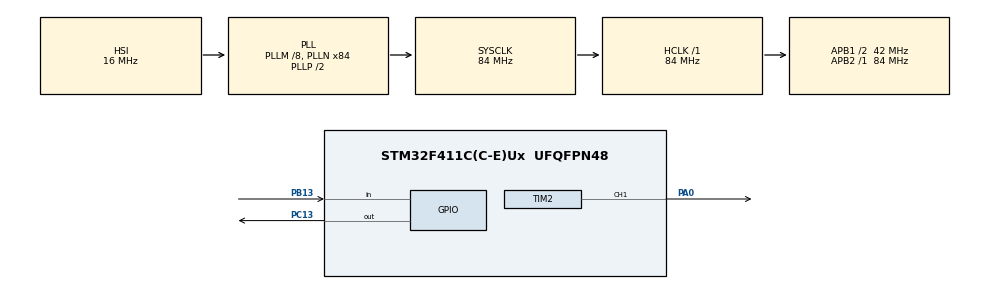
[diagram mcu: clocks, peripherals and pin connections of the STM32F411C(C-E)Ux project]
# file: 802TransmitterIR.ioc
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Mcu.Family=STM32F4
Mcu.Name=STM32F411C(C-E)Ux
Mcu.Package=UFQFPN48
NVIC.PriorityGroup=NVIC_PRIORITYGROUP_4
NVIC.TIM3_IRQn=true\:0\:0\:false\:false\:true\:true\:true\:true
PA0-WKUP.Signal=S_TIM2_CH1_ETR
PB13.GPIO_PuPd=GPIO_PULLUP
PB13.Signal=GPIO_Input
PC13-ANTI_TAMP.Signal=GPIO_Output
ProjectManager.HeapSize=0x200
ProjectManager.StackSize=0x400
ProjectManager.TargetToolchain=STM32CubeIDE
RCC.48MHZClocksFreq_Value=42000000
RCC.AHBFreq_Value=84000000
RCC.APB1CLKDivider=RCC_HCLK_DIV2
RCC.APB1Freq_Value=42000000
RCC.APB1TimFreq_Value=84000000
RCC.APB2Freq_Value=84000000
RCC.APB2TimFreq_Value=84000000
RCC.CortexFreq_Value=84000000
RCC.HCLKFreq_Value=84000000
RCC.HSE_VALUE=25000000
RCC.HSI_VALUE=16000000
RCC.LSE_VALUE=32768
RCC.PLLM=8
RCC.PLLN=84
RCC.SYSCLKFreq_VALUE=84000000
RCC.SYSCLKSource=RCC_SYSCLKSOURCE_PLLCLK
RCC.VCOOutputFreq_Value=168000000
SH.S_TIM2_CH1_ETR.0=TIM2_CH1,PWM Generation1 CH1
TIM2.Channel-PWM\ Generation1\ CH1=TIM_CHANNEL_1
TIM2.Period=28 - 1
TIM2.Prescaler=84 - 1
TIM2.Pulse-PWM\ Generation1\ CH1=14
TIM3.Period=889 - 1
TIM3.Prescaler=84 - 1
VP_TIM2_VS_ClockSourceINT.Mode=Internal
VP_TIM3_VS_ClockSourceINT.Mode=Internal
board=custom

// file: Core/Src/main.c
/* USER CODE BEGIN Header */
/**
  ******************************************************************************
  * @file           : main.c
  * @brief          : Main program body
  ******************************************************************************
  * @attention
  *
  * Copyright (c) 2025 STMicroelectronics.
  * All rights reserved.
  *
  * This software is licensed under terms that can be found in the LICENSE file
  * in the root directory of this software component.
  * If no LICENSE file comes with this software, it is provided AS-IS.
  *
  ******************************************************************************
  */
/* USER CODE END Header */
#include "main.h"

TIM_HandleTypeDef htim2;
TIM_HandleTypeDef htim3;

/* USER CODE BEGIN PV */
#include <stdint.h>
#include <stdbool.h>

// --- Configuración RC-5 ---
#define RC5_HALF_BIT_TIME_US 889
#define RC5_BIT_COUNT 14

// --- Estado de la transmisión ---
volatile bool rc5_is_transmitting = false;
volatile uint16_t rc5_frame_buffer = 0;
volatile int8_t rc5_bit_index = 0;
volatile bool rc5_is_second_half = false; // ¿Estamos en la 1ª o 2ª mitad del bit?

/* USER CODE END PV */

void SystemClock_Config(void);
static void MX_GPIO_Init(void);
static void MX_TIM2_Init(void);
static void MX_TIM3_Init(void);

int main(void)
{

  /* MCU Configuration--------------------------------------------------------*/

  /* Reset of all peripherals, Initializes the Flash interface and the Systick. */
  HAL_Init();

  /* Configure the system clock */
  SystemClock_Config();

  /* Initialize all configured peripherals */
  MX_GPIO_Init();
  MX_TIM2_Init();
  MX_TIM3_Init();
  /* USER CODE BEGIN 2 */
  // Variable para el bit de toggle del RC-5.
  // Cambia de estado con cada nueva pulsación.
  bool rc5_toggle_bit = false;
  /* USER CODE END 2 */

  /* Infinite loop */
  while (1)
  {

    /* USER CODE BEGIN 3 */

    // 1. Comprobar si el botón está presionado.
    // Como usamos PULL-UP, el estado presionado es GPIO_PIN_RESET (BAJO).
    if (HAL_GPIO_ReadPin(GPIOB, GPIO_PIN_13) == GPIO_PIN_RESET)
    {
      // 2. Antirrebote (debounce) - una pequeña pausa.
      // Esperamos un momento para asegurarnos de que no es un ruido eléctrico.
      HAL_Delay(50); // 50 ms es un valor común.

      // 3. Volver a comprobar si el botón sigue presionado.
      if (HAL_GPIO_ReadPin(GPIOB, GPIO_PIN_13) == GPIO_PIN_RESET)
      {
        // ¡Botón confirmado!
        // Solo enviamos si no hay otra transmisión en curso.
        if (!rc5_is_transmitting)
        {
          // 4. Enviar la trama RC-5.
          // Ejemplo: Dirección 5, Comando 23.
          RC5_SendFrame(5, 23, rc5_toggle_bit);

          // 5. Invertir el bit de toggle para la próxima pulsación.
          rc5_toggle_bit = !rc5_toggle_bit;
        }

        // 6. Esperar a que el botón se suelte.
        // Esto evita que se envíen múltiples tramas si se mantiene pulsado.
        while(HAL_GPIO_ReadPin(GPIOB, GPIO_PIN_13) == GPIO_PIN_RESET)
        {
          // No hacer nada hasta que el pin vuelva a ALTO.
        }
      }
    }

  }
  /* USER CODE END 3 */
}

void SystemClock_Config(void)
{
  RCC_OscInitTypeDef RCC_OscInitStruct = {0};
  RCC_ClkInitTypeDef RCC_ClkInitStruct = {0};

  /** Configure the main internal regulator output voltage
  */
  __HAL_RCC_PWR_CLK_ENABLE();
  __HAL_PWR_VOLTAGESCALING_CONFIG(PWR_REGULATOR_VOLTAGE_SCALE1);

  /** Initializes the RCC Oscillators according to the specified parameters
  * in the RCC_OscInitTypeDef structure.
  */
  RCC_OscInitStruct.OscillatorType = RCC_OSCILLATORTYPE_HSI;
  RCC_OscInitStruct.HSIState = RCC_HSI_ON;
  RCC_OscInitStruct.HSICalibrationValue = RCC_HSICALIBRATION_DEFAULT;
  RCC_OscInitStruct.PLL.PLLState = RCC_PLL_ON;
  RCC_OscInitStruct.PLL.PLLSource = RCC_PLLSOURCE_HSI;
  RCC_OscInitStruct.PLL.PLLM = 8;
  RCC_OscInitStruct.PLL.PLLN = 84;
  RCC_OscInitStruct.PLL.PLLP = RCC_PLLP_DIV2;
  RCC_OscInitStruct.PLL.PLLQ = 4;
  if (HAL_RCC_OscConfig(&RCC_OscInitStruct) != HAL_OK)
  {
    Error_Handler();
  }

  /** Initializes the CPU, AHB and APB buses clocks
  */
  RCC_ClkInitStruct.ClockType = RCC_CLOCKTYPE_HCLK|RCC_CLOCKTYPE_SYSCLK
                              |RCC_CLOCKTYPE_PCLK1|RCC_CLOCKTYPE_PCLK2;
  RCC_ClkInitStruct.SYSCLKSource = RCC_SYSCLKSOURCE_PLLCLK;
  RCC_ClkInitStruct.AHBCLKDivider = RCC_SYSCLK_DIV1;
  RCC_ClkInitStruct.APB1CLKDivider = RCC_HCLK_DIV2;
  RCC_ClkInitStruct.APB2CLKDivider = RCC_HCLK_DIV1;

  if (HAL_RCC_ClockConfig(&RCC_ClkInitStruct, FLASH_LATENCY_2) != HAL_OK)
  {
    Error_Handler();
  }
}

static void MX_TIM2_Init(void)
{

  TIM_ClockConfigTypeDef sClockSourceConfig = {0};
  TIM_MasterConfigTypeDef sMasterConfig = {0};
  TIM_OC_InitTypeDef sConfigOC = {0};

  htim2.Instance = TIM2;
  htim2.Init.Prescaler = 84 - 1;
  htim2.Init.CounterMode = TIM_COUNTERMODE_UP;
  htim2.Init.Period = 28 - 1;
  htim2.Init.ClockDivision = TIM_CLOCKDIVISION_DIV1;
  htim2.Init.AutoReloadPreload = TIM_AUTORELOAD_PRELOAD_DISABLE;
  if (HAL_TIM_Base_Init(&htim2) != HAL_OK)
  {
    Error_Handler();
  }
  sClockSourceConfig.ClockSource = TIM_CLOCKSOURCE_INTERNAL;
  if (HAL_TIM_ConfigClockSource(&htim2, &sClockSourceConfig) != HAL_OK)
  {
    Error_Handler();
  }
  if (HAL_TIM_PWM_Init(&htim2) != HAL_OK)
  {
    Error_Handler();
  }
  sMasterConfig.MasterOutputTrigger = TIM_TRGO_RESET;
  sMasterConfig.MasterSlaveMode = TIM_MASTERSLAVEMODE_DISABLE;
  if (HAL_TIMEx_MasterConfigSynchronization(&htim2, &sMasterConfig) != HAL_OK)
  {
    Error_Handler();
  }
  sConfigOC.OCMode = TIM_OCMODE_PWM1;
  sConfigOC.Pulse = 14;
  sConfigOC.OCPolarity = TIM_OCPOLARITY_HIGH;
  sConfigOC.OCFastMode = TIM_OCFAST_DISABLE;
  if (HAL_TIM_PWM_ConfigChannel(&htim2, &sConfigOC, TIM_CHANNEL_1) != HAL_OK)
  {
    Error_Handler();
  }
  HAL_TIM_MspPostInit(&htim2);

}

static void MX_TIM3_Init(void)
{

  TIM_ClockConfigTypeDef sClockSourceConfig = {0};
  TIM_MasterConfigTypeDef sMasterConfig = {0};

  htim3.Instance = TIM3;
  htim3.Init.Prescaler = 84 - 1;
  htim3.Init.CounterMode = TIM_COUNTERMODE_UP;
  htim3.Init.Period = 889 - 1;
  htim3.Init.ClockDivision = TIM_CLOCKDIVISION_DIV1;
  htim3.Init.AutoReloadPreload = TIM_AUTORELOAD_PRELOAD_DISABLE;
  if (HAL_TIM_Base_Init(&htim3) != HAL_OK)
  {
    Error_Handler();
  }
  sClockSourceConfig.ClockSource = TIM_CLOCKSOURCE_INTERNAL;
  if (HAL_TIM_ConfigClockSource(&htim3, &sClockSourceConfig) != HAL_OK)
  {
    Error_Handler();
  }
  sMasterConfig.MasterOutputTrigger = TIM_TRGO_RESET;
  sMasterConfig.MasterSlaveMode = TIM_MASTERSLAVEMODE_DISABLE;
  if (HAL_TIMEx_MasterConfigSynchronization(&htim3, &sMasterConfig) != HAL_OK)
  {
    Error_Handler();
  }

}

static void MX_GPIO_Init(void)
{
  GPIO_InitTypeDef GPIO_InitStruct = {0};

  /* GPIO Ports Clock Enable */
  __HAL_RCC_GPIOC_CLK_ENABLE();
  __HAL_RCC_GPIOA_CLK_ENABLE();
  __HAL_RCC_GPIOB_CLK_ENABLE();

  /*Configure GPIO pin Output Level */
  HAL_GPIO_WritePin(GPIOC, GPIO_PIN_13, GPIO_PIN_RESET);

  /*Configure GPIO pin : PC13 */
  GPIO_InitStruct.Pin = GPIO_PIN_13;
  GPIO_InitStruct.Mode = GPIO_MODE_OUTPUT_PP;
  GPIO_InitStruct.Pull = GPIO_NOPULL;
  GPIO_InitStruct.Speed = GPIO_SPEED_FREQ_LOW;
  HAL_GPIO_Init(GPIOC, &GPIO_InitStruct);

  /*Configure GPIO pin : PB13 */
  GPIO_InitStruct.Pin = GPIO_PIN_13;
  GPIO_InitStruct.Mode = GPIO_MODE_INPUT;
  GPIO_InitStruct.Pull = GPIO_PULLUP;
  HAL_GPIO_Init(GPIOB, &GPIO_InitStruct);

}

/* USER CODE BEGIN 4 */

/**
 * @brief Prepara y comienza la transmisión de una trama RC-5.
 * @param address: Dirección del dispositivo (0-31)
 * @param command: Comando a enviar (0-63)
 * @param toggle_bit: El bit de toggle (cambia con cada nueva pulsación)
 */
void RC5_SendFrame(uint8_t address, uint8_t command, bool toggle_bit) {
    if (rc5_is_transmitting) {
        return; // Ya hay una transmisión en curso
    }

    // Construcción de la trama de 14 bits
    // | S2 | S1 | T | A4 A3 A2 A1 A0 | C5 C4 C3 C2 C1 C0 |
    // S2 es un bit extendido (siempre '1' para el estándar RC-5)
    // S1 es el bit de start (siempre '1')
    rc5_frame_buffer = (1 << 13) | (1 << 12) | ((toggle_bit & 1) << 11) |
                       ((address & 0x1F) << 6) | (command & 0x3F);

    // Inicializar estado de transmisión
    rc5_bit_index = RC5_BIT_COUNT - 1; // Empezamos por el bit más significativo (S2)
    rc5_is_second_half = false;
    rc5_is_transmitting = true;

    // Arrancamos el timer de temporización. La ISR se encargará del resto.
    HAL_TIM_Base_Start_IT(&htim3);
}

// Apaga el LED y detiene la transmisión
void RC5_StopTransmission() {
    rc5_is_transmitting = false;
    HAL_TIM_PWM_Stop(&htim2, TIM_CHANNEL_1); // Apaga la portadora
    HAL_TIM_Base_Stop_IT(&htim3); // Detiene las interrupciones de temporización
}

/**
 * @brief Callback que se ejecuta cuando el timer de temporización (TIM3) se desborda.
 * Se llama cada 889us.
 */
void HAL_TIM_PeriodElapsedCallback(TIM_HandleTypeDef *htim) {
    if (htim->Instance == TIM3) { // Asegurarnos de que es nuestro timer
        if (!rc5_is_transmitting) {
            RC5_StopTransmission();
            return;
        }

        // Extraemos el bit actual que queremos transmitir
        bool current_bit = (rc5_frame_buffer >> rc5_bit_index) & 1;

        // Lógica de codificación Manchester
        // bit '0': Bajo -> Alto
        // bit '1': Alto -> Bajo
        if (current_bit == 0) { // Enviar un '0'
            if (!rc5_is_second_half) {
                // Primera mitad: BAJO (PWM apagado)
                HAL_TIM_PWM_Stop(&htim2, TIM_CHANNEL_1);
            } else {
                // Segunda mitad: ALTO (PWM encendido)
                HAL_TIM_PWM_Start(&htim2, TIM_CHANNEL_1);
            }
        } else { // Enviar un '1'
            if (!rc5_is_second_half) {
                // Primera mitad: ALTO (PWM encendido)
                HAL_TIM_PWM_Start(&htim2, TIM_CHANNEL_1);
            } else {
                // Segunda mitad: BAJO (PWM apagado)
                HAL_TIM_PWM_Stop(&htim2, TIM_CHANNEL_1);
            }
        }

        // Avanzamos al siguiente estado
        if (rc5_is_second_half) {
            rc5_bit_index--; // Hemos terminado un bit completo, pasamos al siguiente
        }
        rc5_is_second_half = !rc5_is_second_half; // Cambiamos de mitad de bit

        // Si ya hemos enviado todos los bits, terminamos
        if (rc5_bit_index < 0) {
            RC5_StopTransmission();
        }
    }
}

/* USER CODE END 4 */

void Error_Handler(void)
{
  __disable_irq();
  while (1)
  {
  }
}
